# STM32G483 register map
File version: 2.8
CPU: CM4 r0p1, little endian, MPU, FPU, 4 interrupt priority bits
Registers are 32-bit, read-write, reset 0x0 unless marked. A register's access mark holds for its fields unless they carry their own. Offsets are from the block's base; [hi:lo] are bit positions.

## FLASH
Base 0x40022000
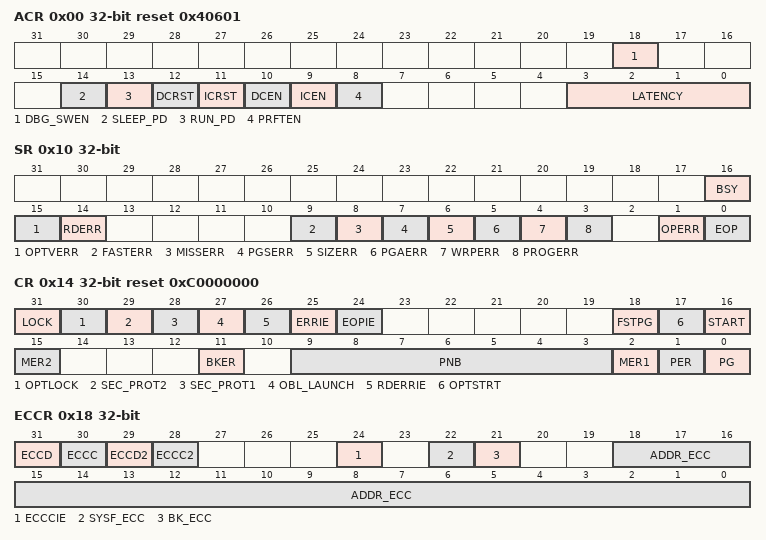
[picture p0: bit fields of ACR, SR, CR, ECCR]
0x00 ACR reset 0x40601 — Flash access control register
  [18] DBG_SWEN — Debug software enable
  [14] SLEEP_PD — Flash Power-down mode during Sleep or Low-power sleep mode
  [13] RUN_PD — Flash Power-down mode during Run or Low-power run mode
  [12] DCRST — Data cache reset
  [11] ICRST — Instruction cache reset
  [10] DCEN — Data cache enable
  [9] ICEN — Instruction cache enable
  [8] PRFTEN — Prefetch enable
  [3:0] LATENCY
    0=Wait0 (Zero Wait States (Vcore Boost 1 (<= 34MHz), Vcore Normal 1 (<= 30MHz), Vcore 2 (<= 12MHz)); 1=Wait1 (One Wait State (Vcore Boost 1 (<= 68MHz), Vcore Normal 1 (<= 60MHz), Vcore 2 (<= 24MHz)); 2=Wait2 (Two Wait States (Vcore Boost 1 (<= 102MHz), Vcore Normal 1 (<= 90MHz), Vcore 2 (<= 26MHz)); 3=Wait3 (Three Wait States (Vcore Boost 1 (<= 136MHz), Vcore Normal 1 (<= 120MHz)); 4=Wait4 (Four Wait States (Vcore Boost 1 (<= 170MHz), Vcore Normal 1 (<= 150MHz))
0x04 PDKEYR wo — Flash Power-down key register
  [31:0] PDKEYR — Power-down in Run mode Flash key
0x08 KEYR wo — Flash key register
  [31:0] KEYR — Flash key
0x0C OPTKEYR wo — Flash option key register
  [31:0] OPTKEYR — Option byte key
0x10 SR — Flash status register
  [16] BSY ro — Busy
  [15] OPTVERR — Option validity error
  [14] RDERR — PCROP read error
  [9] FASTERR — Fast programming error
  [8] MISSERR — Fast programming data miss error
  [7] PGSERR — Programming sequence error
  [6] SIZERR — Size error
  [5] PGAERR — Programming alignment error
  [4] WRPERR — Write protection error
  [3] PROGERR — Programming error
  [1] OPERR — Operation error
  [0] EOP — End of operation
0x14 CR reset 0xC0000000 — Flash control register
  [31] LOCK — FLASH_CR Lock
  [30] OPTLOCK — Options Lock
  [29] SEC_PROT2 — Securable memory area protection bit for bank 2.
  [28] SEC_PROT1 — Securable memory area protection bit for bank 1.
  [27] OBL_LAUNCH — Force the option byte loading
  [26] RDERRIE — PCROP read error interrupt enable
  [25] ERRIE — Error interrupt enable
  [24] EOPIE — End of operation interrupt enable
  [18] FSTPG — Fast programming
  [17] OPTSTRT — Options modification start
  [16] START
  [15] MER2 — Bank 2 Mass erase
  [11] BKER — Bank erase
    0=Bank 1 is selected for page erase; 1=Bank 2 is selected for page erase
  [9:3] PNB — Page number selection
  [2] MER1 — Bank 1 Mass erase
  [1] PER — Page erase
  [0] PG — Programming
0x18 ECCR — Flash ECC register
  [31] ECCD — ECC detection
  [30] ECCC — ECC correction
  [29] ECCD2 — ECC2 detection
  [28] ECCC2 — ECC correction
  [24] ECCCIE — ECC correction interrupt enable
  [22] SYSF_ECC ro — System Flash ECC fail
  [21] BK_ECC ro — ECC fail bank
  [18:0] ADDR_ECC ro — ECC fail address
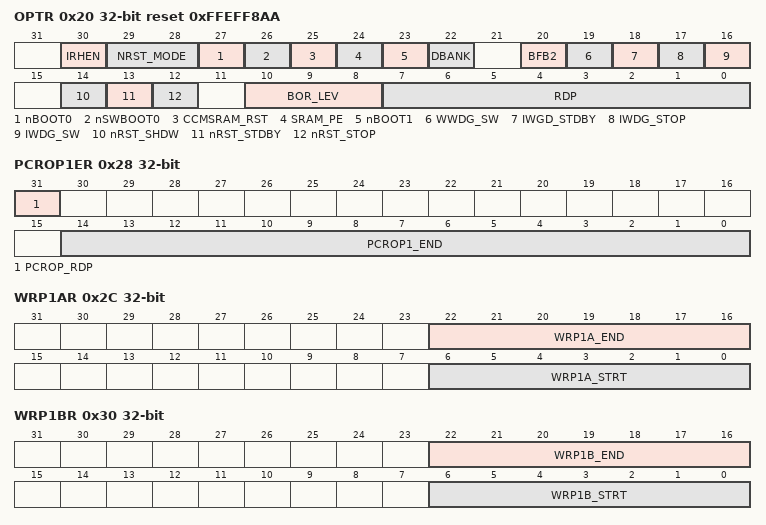
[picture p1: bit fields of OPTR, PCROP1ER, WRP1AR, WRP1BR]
0x20 OPTR reset 0xFFEFF8AA
  [30] IRHEN — Internal reset holder enable bit
  [29:28] NRST_MODE
  [27] nBOOT0 — nBOOT0 option bit
  [26] nSWBOOT0 — Software BOOT0
  [25] CCMSRAM_RST
  [24] SRAM_PE — SRAM1 and CCM SRAM parity check enable
  [23] nBOOT1 — Boot configuration
  [22] DBANK — This bit can only be written when PCROPA/B is disabled.
    0=Single-bank mode with 128 bits data read width; 1=Dual-bank mode with 64 bits data
  [20] BFB2 — Dual-bank boot
    0=Disabled (Boot from memory bank 1); 1=Enabled (Boot from memory bank 2)
  [19] WWDG_SW — Window watchdog selection
  [18] IWGD_STDBY
  [17] IWDG_STOP
  [16] IWDG_SW — Independent watchdog selection
  [14] nRST_SHDW
  [13] nRST_STDBY
  [12] nRST_STOP
  [10:8] BOR_LEV — BOR reset Level
  [7:0] RDP — Read protection level
0x24 PCROP1SR reset 0xFFFF0000 (reset mask 0xFFFF0000) — Flash PCROP1 Start address register
  [14:0] PCROP1_STRT — PCROP area start offset
0x28 PCROP1ER (reset mask 0xFFF0000) — Flash PCROP1 End address register
  [31] PCROP_RDP — PCROP area preserved when RDP level decreased
  [14:0] PCROP1_END — Bank 1 PCROP area end offset
0x2C WRP1AR (reset mask 0xFF00FF00) — Flash Bank 1 WRP area A address register
  [22:16] WRP1A_END — WRP first area A end offset
  [6:0] WRP1A_STRT — WRP first area A start offset
0x30 WRP1BR (reset mask 0xFF00FF00) — Flash Bank 1 WRP area B address register
  [22:16] WRP1B_END — WRP second area B end offset
  [6:0] WRP1B_STRT — WRP second area B start offset
0x44 PCROP2SR reset 0xFFFF0000 (reset mask 0xFFFF0000) — Flash PCROP2 Start address register
  [14:0] PCROP2_STRT — PCROP area start offset
0x48 PCROP2ER (reset mask 0xFFFF0000) — Flash PCROP2 End address register
  [14:0] PCROP2_END — PCROP area end offset
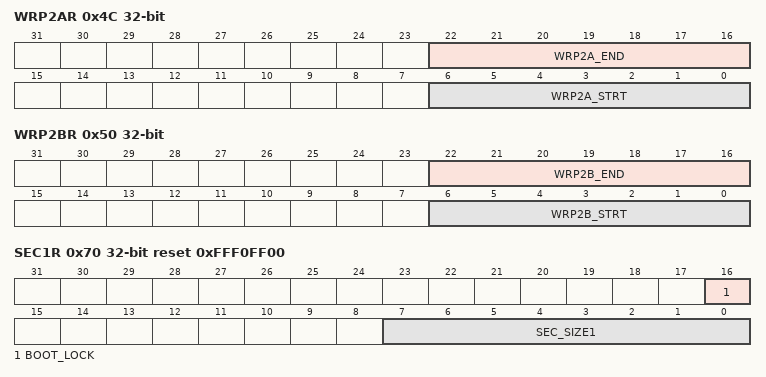
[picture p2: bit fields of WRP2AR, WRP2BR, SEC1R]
0x4C WRP2AR (reset mask 0xFF00FF00) — Flash Bank 2 WRP area A address register
  [22:16] WRP2A_END — WRP first area A end offset
  [6:0] WRP2A_STRT — WRP first area A start offset
0x50 WRP2BR (reset mask 0xFF00FF00) — Flash Bank 2 WRP area B address register
  [22:16] WRP2B_END — WRP second area B end offset
  [6:0] WRP2B_STRT — WRP second area B start offset
0x70 SEC1R reset 0xFFF0FF00 (reset mask 0xFFF0FF00) — Flash Securable area bank1 register
  [16] BOOT_LOCK — used to force boot from user Flash area.
  [7:0] SEC_SIZE1 — sets the number of pages used in the bank 1 Securable memory area.
0x74 SEC2R reset 0xFFFFFF00 (reset mask 0xFFFFFF00) — Flash Securable area bank2 register
  [7:0] SEC_SIZE2 — sets the number of pages used in the bank 2 Securable memory area.
